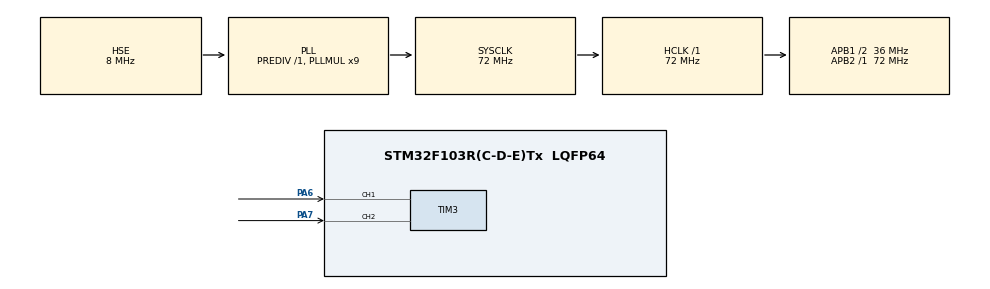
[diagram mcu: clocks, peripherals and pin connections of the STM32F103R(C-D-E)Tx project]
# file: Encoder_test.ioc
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Mcu.Family=STM32F1
Mcu.Name=STM32F103R(C-D-E)Tx
Mcu.Package=LQFP64
NVIC.PriorityGroup=NVIC_PRIORITYGROUP_4
PA13.Mode=Serial_Wire
PA13.Signal=SYS_JTMS-SWDIO
PA14.Mode=Serial_Wire
PA14.Signal=SYS_JTCK-SWCLK
PA6.Signal=S_TIM3_CH1
PA7.Signal=S_TIM3_CH2
PD0-OSC_IN.Mode=HSE-External-Oscillator
PD0-OSC_IN.Signal=RCC_OSC_IN
PD1-OSC_OUT.Mode=HSE-External-Oscillator
PD1-OSC_OUT.Signal=RCC_OSC_OUT
ProjectManager.HeapSize=0x200
ProjectManager.StackSize=0x400
ProjectManager.TargetToolchain=Makefile
RCC.AHBFreq_Value=72000000
RCC.APB1CLKDivider=RCC_HCLK_DIV2
RCC.APB1Freq_Value=36000000
RCC.APB1TimFreq_Value=72000000
RCC.APB2Freq_Value=72000000
RCC.APB2TimFreq_Value=72000000
RCC.HCLKFreq_Value=72000000
RCC.PLLMUL=RCC_PLL_MUL9
RCC.PLLSourceVirtual=RCC_PLLSOURCE_HSE
RCC.SYSCLKFreq_VALUE=72000000
RCC.SYSCLKSource=RCC_SYSCLKSOURCE_PLLCLK
RCC.USBFreq_Value=72000000
SH.S_TIM3_CH1.0=TIM3_CH1,Encoder_Interface
SH.S_TIM3_CH2.0=TIM3_CH2,Encoder_Interface
TIM3.EncoderMode=TIM_ENCODERMODE_TI12
TIM3.IC1Filter=15
TIM3.IC2Filter=15
board=custom

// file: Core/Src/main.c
/* USER CODE BEGIN Header */
/**
  ******************************************************************************
  * @file           : main.c
  * @brief          : Main program body
  ******************************************************************************
  * @attention
  *
  * Copyright (c) 2026 STMicroelectronics.
  * All rights reserved.
  *
  * This software is licensed under terms that can be found in the LICENSE file
  * in the root directory of this software component.
  * If no LICENSE file comes with this software, it is provided AS-IS.
  *
  ******************************************************************************
  */
/* USER CODE END Header */
#include "main.h"
#include "tim.h"
#include "gpio.h"

/* USER CODE BEGIN Includes */
#include "stdio.h"
/* USER CODE END Includes */

/* USER CODE BEGIN PV */
int32_t start_cnt = 0;
int32_t end_cnt = 0;
int32_t delta = 0;

/* USER CODE END PV */

void SystemClock_Config(void);
/* USER CODE BEGIN PFP */
int32_t Encoder_Get(void)
{
    return (int32_t)__HAL_TIM_GET_COUNTER(&htim3);
}
/* USER CODE END PFP */

int main(void)
{

  /* MCU Configuration--------------------------------------------------------*/

  /* Reset of all peripherals, Initializes the Flash interface and the Systick. */
  HAL_Init();

  /* Configure the system clock */
  SystemClock_Config();

  /* Initialize all configured peripherals */
  MX_GPIO_Init();
  MX_TIM3_Init();
  /* USER CODE BEGIN 2 */
  HAL_TIM_Encoder_Start(&htim3, TIM_CHANNEL_ALL);
  HAL_Delay(3000);          // 给你时间准备

  start_cnt = __HAL_TIM_GET_COUNTER(&htim3);

  HAL_Delay(5000);          // 5秒内手转一圈

  end_cnt = __HAL_TIM_GET_COUNTER(&htim3);

  delta = end_cnt - start_cnt;
  /* USER CODE END 2 */

  /* Infinite loop */
  while (1)
  {

    /* USER CODE BEGIN 3 */
    __NOP();
  }
  /* USER CODE END 3 */
}

void SystemClock_Config(void)
{
  RCC_OscInitTypeDef RCC_OscInitStruct = {0};
  RCC_ClkInitTypeDef RCC_ClkInitStruct = {0};

  /** Initializes the RCC Oscillators according to the specified parameters
  * in the RCC_OscInitTypeDef structure.
  */
  RCC_OscInitStruct.OscillatorType = RCC_OSCILLATORTYPE_HSE;
  RCC_OscInitStruct.HSEState = RCC_HSE_ON;
  RCC_OscInitStruct.HSEPredivValue = RCC_HSE_PREDIV_DIV1;
  RCC_OscInitStruct.HSIState = RCC_HSI_ON;
  RCC_OscInitStruct.PLL.PLLState = RCC_PLL_ON;
  RCC_OscInitStruct.PLL.PLLSource = RCC_PLLSOURCE_HSE;
  RCC_OscInitStruct.PLL.PLLMUL = RCC_PLL_MUL9;
  if (HAL_RCC_OscConfig(&RCC_OscInitStruct) != HAL_OK)
  {
    Error_Handler();
  }

  /** Initializes the CPU, AHB and APB buses clocks
  */
  RCC_ClkInitStruct.ClockType = RCC_CLOCKTYPE_HCLK|RCC_CLOCKTYPE_SYSCLK
                              |RCC_CLOCKTYPE_PCLK1|RCC_CLOCKTYPE_PCLK2;
  RCC_ClkInitStruct.SYSCLKSource = RCC_SYSCLKSOURCE_PLLCLK;
  RCC_ClkInitStruct.AHBCLKDivider = RCC_SYSCLK_DIV1;
  RCC_ClkInitStruct.APB1CLKDivider = RCC_HCLK_DIV2;
  RCC_ClkInitStruct.APB2CLKDivider = RCC_HCLK_DIV1;

  if (HAL_RCC_ClockConfig(&RCC_ClkInitStruct, FLASH_LATENCY_2) != HAL_OK)
  {
    Error_Handler();
  }
}

void Error_Handler(void)
{
  __disable_irq();
  while (1)
  {
  }
}
